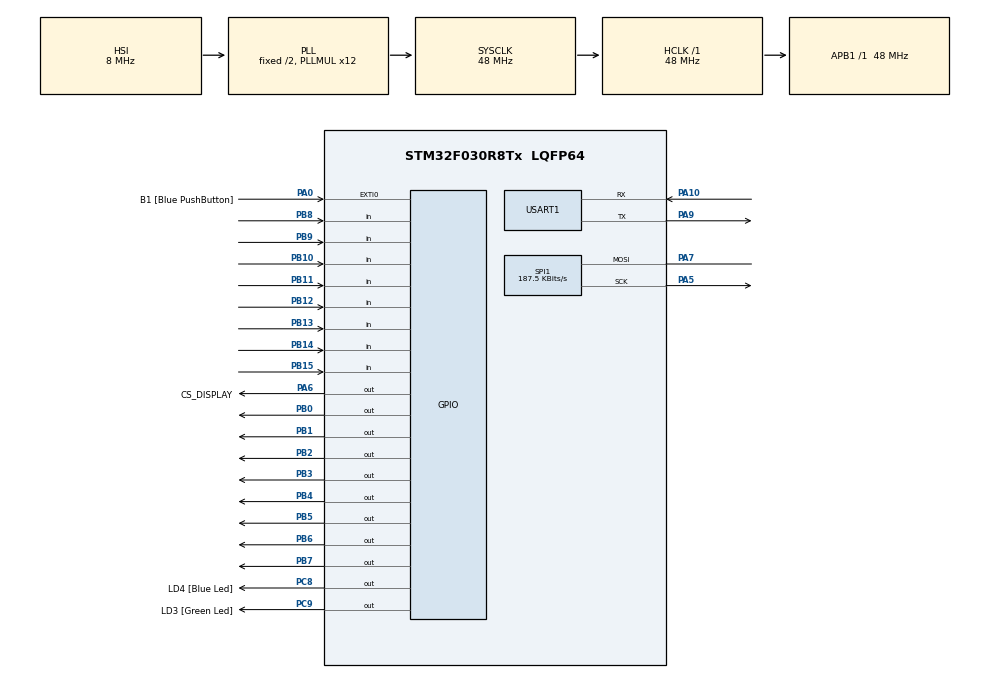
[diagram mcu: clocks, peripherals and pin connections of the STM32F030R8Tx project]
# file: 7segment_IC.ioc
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Mcu.Family=STM32F0
Mcu.Name=STM32F030R8Tx
Mcu.Package=LQFP64
PA0.GPIO_Label=B1 [Blue PushButton]
PA0.GPIO_ModeDefaultEXTI=GPIO_MODE_EVT_RISING
PA0.Signal=GPXTI0
PA10.Mode=Asynchronous
PA10.Signal=USART1_RX
PA13.GPIO_Label=SWDIO
PA13.Signal=SYS_SWDIO
PA14.GPIO_Label=SWCLK
PA14.Signal=SYS_SWCLK
PA5.Mode=Simplex_Bidirectional_Master
PA5.Signal=SPI1_SCK
PA6.GPIO_Label=CS_DISPLAY
PA6.Signal=GPIO_Output
PA7.Mode=Simplex_Bidirectional_Master
PA7.Signal=SPI1_MOSI
PA9.Mode=Asynchronous
PA9.Signal=USART1_TX
PB0.Signal=GPIO_Output
PB1.Signal=GPIO_Output
PB10.Signal=GPIO_Input
PB11.Signal=GPIO_Input
PB12.Signal=GPIO_Input
PB13.Signal=GPIO_Input
PB14.Signal=GPIO_Input
PB15.Signal=GPIO_Input
PB2.Signal=GPIO_Output
PB3.Signal=GPIO_Output
PB4.Signal=GPIO_Output
PB5.Signal=GPIO_Output
PB6.Signal=GPIO_Output
PB7.Signal=GPIO_Output
PB8.Signal=GPIO_Input
PB9.Signal=GPIO_Input
PC8.GPIO_Label=LD4 [Blue Led]
PC8.Signal=GPIO_Output
PC9.GPIO_Label=LD3 [Green Led]
PC9.Signal=GPIO_Output
ProjectManager.HeapSize=0x200
ProjectManager.StackSize=0x400
ProjectManager.TargetToolchain=TrueSTUDIO
RCC.AHBFreq_Value=48000000
RCC.APB1Freq_Value=48000000
RCC.APB1TimFreq_Value=48000000
RCC.HCLKFreq_Value=48000000
RCC.PLLMUL=RCC_PLL_MUL12
RCC.SYSCLKFreq_VALUE=48000000
RCC.SYSCLKSource=RCC_SYSCLKSOURCE_PLLCLK
SPI1.BaudRatePrescaler=SPI_BAUDRATEPRESCALER_256
SPI1.CalculateBaudRate=187.5 KBits/s
SPI1.DataSize=SPI_DATASIZE_8BIT
SPI1.Direction=SPI_DIRECTION_1LINE
SPI1.Mode=SPI_MODE_MASTER
SPI1.VirtualType=VM_MASTER
USART1.VirtualMode-Asynchronous=VM_ASYNC
board=32F0308DISCOVERY

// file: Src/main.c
/* USER CODE BEGIN Header */
/**
  ******************************************************************************
  * @file           : main.c
  * @brief          : Main program body
  ******************************************************************************
  * @attention
  *
  * <h2><center>&copy; Copyright (c) 2019 STMicroelectronics.
  * All rights reserved.</center></h2>
  *
  * This software component is licensed by ST under BSD 3-Clause license,
  * the "License"; You may not use this file except in compliance with the
  * License. You may obtain a copy of the License at:
  *                        opensource.org/licenses/BSD-3-Clause
  *
  ******************************************************************************
  */
/* USER CODE END Header */

#include "main.h"

/* USER CODE BEGIN Includes */
#include "max7219.h"
/* USER CODE END Includes */

SPI_HandleTypeDef hspi1;

UART_HandleTypeDef huart1;

void SystemClock_Config(void);
static void MX_GPIO_Init(void);
static void MX_SPI1_Init(void);
static void MX_USART1_UART_Init(void);

/* USER CODE BEGIN 0 */
void blink_led(void){
	static uint32_t led_blink_period = 0;
	if (HAL_GetTick()> led_blink_period) {
		led_blink_period = HAL_GetTick()+ 500;
		GPIOC->ODR ^= GPIO_PIN_8;
	}

}
/* USER CODE END 0 */

int main(void)
{

  /* MCU Configuration--------------------------------------------------------*/

  /* Reset of all peripherals, Initializes the Flash interface and the Systick. */
  HAL_Init();

  /* USER CODE BEGIN Init */
  setvbuf(stdout, NULL, _IONBF, 0);

  /* USER CODE END Init */

  /* Configure the system clock */
  SystemClock_Config();

  /* Initialize all configured peripherals */
  MX_GPIO_Init();
  MX_SPI1_Init();
  MX_USART1_UART_Init();
  /* USER CODE BEGIN 2 */
	printf("Program start \r\n");
	max7219_init();
  /* USER CODE END 2 */

  /* Infinite loop */
  while (1)
  {

    /* USER CODE BEGIN 3 */
    blink_led();
    show_animation();

    //show_seconds();
  }
  /* USER CODE END 3 */
}

void SystemClock_Config(void)
{
  RCC_OscInitTypeDef RCC_OscInitStruct = {0};
  RCC_ClkInitTypeDef RCC_ClkInitStruct = {0};
  RCC_PeriphCLKInitTypeDef PeriphClkInit = {0};

  /** Initializes the CPU, AHB and APB busses clocks
  */
  RCC_OscInitStruct.OscillatorType = RCC_OSCILLATORTYPE_HSI;
  RCC_OscInitStruct.HSIState = RCC_HSI_ON;
  RCC_OscInitStruct.HSICalibrationValue = RCC_HSICALIBRATION_DEFAULT;
  RCC_OscInitStruct.PLL.PLLState = RCC_PLL_ON;
  RCC_OscInitStruct.PLL.PLLSource = RCC_PLLSOURCE_HSI;
  RCC_OscInitStruct.PLL.PLLMUL = RCC_PLL_MUL12;
  RCC_OscInitStruct.PLL.PREDIV = RCC_PREDIV_DIV1;
  if (HAL_RCC_OscConfig(&RCC_OscInitStruct) != HAL_OK)
  {
    Error_Handler();
  }
  /** Initializes the CPU, AHB and APB busses clocks
  */
  RCC_ClkInitStruct.ClockType = RCC_CLOCKTYPE_HCLK|RCC_CLOCKTYPE_SYSCLK
                              |RCC_CLOCKTYPE_PCLK1;
  RCC_ClkInitStruct.SYSCLKSource = RCC_SYSCLKSOURCE_PLLCLK;
  RCC_ClkInitStruct.AHBCLKDivider = RCC_SYSCLK_DIV1;
  RCC_ClkInitStruct.APB1CLKDivider = RCC_HCLK_DIV1;

  if (HAL_RCC_ClockConfig(&RCC_ClkInitStruct, FLASH_LATENCY_1) != HAL_OK)
  {
    Error_Handler();
  }
  PeriphClkInit.PeriphClockSelection = RCC_PERIPHCLK_USART1;
  PeriphClkInit.Usart1ClockSelection = RCC_USART1CLKSOURCE_PCLK1;
  if (HAL_RCCEx_PeriphCLKConfig(&PeriphClkInit) != HAL_OK)
  {
    Error_Handler();
  }
}

static void MX_SPI1_Init(void)
{

  /* SPI1 parameter configuration*/
  hspi1.Instance = SPI1;
  hspi1.Init.Mode = SPI_MODE_MASTER;
  hspi1.Init.Direction = SPI_DIRECTION_1LINE;
  hspi1.Init.DataSize = SPI_DATASIZE_8BIT;
  hspi1.Init.CLKPolarity = SPI_POLARITY_LOW;
  hspi1.Init.CLKPhase = SPI_PHASE_1EDGE;
  hspi1.Init.NSS = SPI_NSS_SOFT;
  hspi1.Init.BaudRatePrescaler = SPI_BAUDRATEPRESCALER_256;
  hspi1.Init.FirstBit = SPI_FIRSTBIT_MSB;
  hspi1.Init.TIMode = SPI_TIMODE_DISABLE;
  hspi1.Init.CRCCalculation = SPI_CRCCALCULATION_DISABLE;
  hspi1.Init.CRCPolynomial = 7;
  hspi1.Init.CRCLength = SPI_CRC_LENGTH_DATASIZE;
  hspi1.Init.NSSPMode = SPI_NSS_PULSE_ENABLE;
  if (HAL_SPI_Init(&hspi1) != HAL_OK)
  {
    Error_Handler();
  }

}

static void MX_USART1_UART_Init(void)
{

  huart1.Instance = USART1;
  huart1.Init.BaudRate = 38400;
  huart1.Init.WordLength = UART_WORDLENGTH_8B;
  huart1.Init.StopBits = UART_STOPBITS_1;
  huart1.Init.Parity = UART_PARITY_NONE;
  huart1.Init.Mode = UART_MODE_TX_RX;
  huart1.Init.HwFlowCtl = UART_HWCONTROL_NONE;
  huart1.Init.OverSampling = UART_OVERSAMPLING_16;
  huart1.Init.OneBitSampling = UART_ONE_BIT_SAMPLE_DISABLE;
  huart1.AdvancedInit.AdvFeatureInit = UART_ADVFEATURE_NO_INIT;
  if (HAL_UART_Init(&huart1) != HAL_OK)
  {
    Error_Handler();
  }

}

static void MX_GPIO_Init(void)
{
  GPIO_InitTypeDef GPIO_InitStruct = {0};

  /* GPIO Ports Clock Enable */
  __HAL_RCC_GPIOA_CLK_ENABLE();
  __HAL_RCC_GPIOB_CLK_ENABLE();
  __HAL_RCC_GPIOC_CLK_ENABLE();

  /*Configure GPIO pin Output Level */
  HAL_GPIO_WritePin(CS_DISPLAY_GPIO_Port, CS_DISPLAY_Pin, GPIO_PIN_RESET);

  /*Configure GPIO pin Output Level */
  HAL_GPIO_WritePin(GPIOB, GPIO_PIN_0|GPIO_PIN_1|GPIO_PIN_2|GPIO_PIN_3
                          |GPIO_PIN_4|GPIO_PIN_5|GPIO_PIN_6|GPIO_PIN_7, GPIO_PIN_RESET);

  /*Configure GPIO pin Output Level */
  HAL_GPIO_WritePin(GPIOC, LD4_Pin|LD3_Pin, GPIO_PIN_RESET);

  /*Configure GPIO pin : B1_Pin */
  GPIO_InitStruct.Pin = B1_Pin;
  GPIO_InitStruct.Mode = GPIO_MODE_EVT_RISING;
  GPIO_InitStruct.Pull = GPIO_NOPULL;
  HAL_GPIO_Init(B1_GPIO_Port, &GPIO_InitStruct);

  /*Configure GPIO pin : CS_DISPLAY_Pin */
  GPIO_InitStruct.Pin = CS_DISPLAY_Pin;
  GPIO_InitStruct.Mode = GPIO_MODE_OUTPUT_PP;
  GPIO_InitStruct.Pull = GPIO_NOPULL;
  GPIO_InitStruct.Speed = GPIO_SPEED_FREQ_LOW;
  HAL_GPIO_Init(CS_DISPLAY_GPIO_Port, &GPIO_InitStruct);

  /*Configure GPIO pins : PB0 PB1 PB2 PB3
                           PB4 PB5 PB6 PB7 */
  GPIO_InitStruct.Pin = GPIO_PIN_0|GPIO_PIN_1|GPIO_PIN_2|GPIO_PIN_3
                          |GPIO_PIN_4|GPIO_PIN_5|GPIO_PIN_6|GPIO_PIN_7;
  GPIO_InitStruct.Mode = GPIO_MODE_OUTPUT_PP;
  GPIO_InitStruct.Pull = GPIO_NOPULL;
  GPIO_InitStruct.Speed = GPIO_SPEED_FREQ_LOW;
  HAL_GPIO_Init(GPIOB, &GPIO_InitStruct);

  /*Configure GPIO pins : PB10 PB11 PB12 PB13
                           PB14 PB15 PB8 PB9 */
  GPIO_InitStruct.Pin = GPIO_PIN_10|GPIO_PIN_11|GPIO_PIN_12|GPIO_PIN_13
                          |GPIO_PIN_14|GPIO_PIN_15|GPIO_PIN_8|GPIO_PIN_9;
  GPIO_InitStruct.Mode = GPIO_MODE_INPUT;
  GPIO_InitStruct.Pull = GPIO_NOPULL;
  HAL_GPIO_Init(GPIOB, &GPIO_InitStruct);

  /*Configure GPIO pins : LD4_Pin LD3_Pin */
  GPIO_InitStruct.Pin = LD4_Pin|LD3_Pin;
  GPIO_InitStruct.Mode = GPIO_MODE_OUTPUT_PP;
  GPIO_InitStruct.Pull = GPIO_NOPULL;
  GPIO_InitStruct.Speed = GPIO_SPEED_FREQ_LOW;
  HAL_GPIO_Init(GPIOC, &GPIO_InitStruct);

}

void Error_Handler(void)
{
}

/************************ (C) COPYRIGHT STMicroelectronics *****END OF FILE****/
